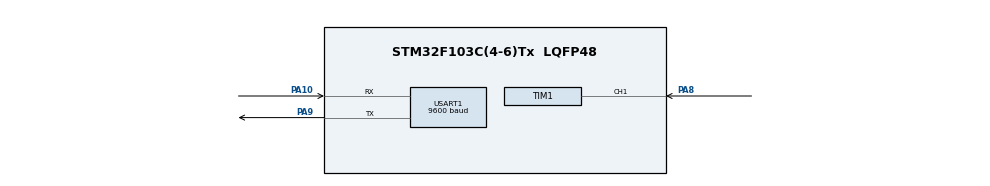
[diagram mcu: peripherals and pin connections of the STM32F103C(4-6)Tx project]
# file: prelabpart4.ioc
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Mcu.Family=STM32F1
Mcu.Name=STM32F103C(4-6)Tx
Mcu.Package=LQFP48
NVIC.PriorityGroup=NVIC_PRIORITYGROUP_4
NVIC.TIM1_BRK_IRQn=true\:0\:0\:false\:false\:true\:true\:true
NVIC.TIM1_CC_IRQn=true\:0\:0\:false\:false\:true\:true\:true
NVIC.TIM1_TRG_COM_IRQn=true\:0\:0\:false\:false\:true\:true\:true
NVIC.TIM1_UP_IRQn=true\:0\:0\:false\:false\:true\:true\:true
NVIC.USART1_IRQn=true\:0\:0\:false\:false\:true\:true\:true
PA10.Mode=Asynchronous
PA10.Signal=USART1_RX
PA8.Signal=S_TIM1_CH1
PA9.Mode=Asynchronous
PA9.Signal=USART1_TX
ProjectManager.HeapSize=0x200
ProjectManager.StackSize=0x400
ProjectManager.TargetToolchain=MDK-ARM V5.32
RCC.APB1Freq_Value=8000000
RCC.APB2Freq_Value=8000000
SH.S_TIM1_CH1.0=TIM1_CH1,Input_Capture1_from_TI1
TIM1.Channel-Input_Capture1_from_TI1=TIM_CHANNEL_1
TIM1.Period=63999
TIM1.Prescaler=124
USART1.BaudRate=9600
USART1.Mode=MODE_TX
USART1.VirtualMode=VM_ASYNC
VP_SYS_VS_ND.Mode=No_Debug
VP_TIM1_VS_ClockSourceINT.Mode=Internal
board=custom

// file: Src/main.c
/* USER CODE BEGIN Header */
/**
  ******************************************************************************
  * @file           : main.c
  * @brief          : Main program body
  ******************************************************************************
  * @attention
  *
  * Copyright (c) 2022 STMicroelectronics.
  * All rights reserved.
  *
  * This software is licensed under terms that can be found in the LICENSE file
  * in the root directory of this software component.
  * If no LICENSE file comes with this software, it is provided AS-IS.
  *
  ******************************************************************************
  */
/* USER CODE END Header */
#include "main.h"

TIM_HandleTypeDef htim1;

UART_HandleTypeDef huart1;

void SystemClock_Config(void);
static void MX_GPIO_Init(void);
static void MX_TIM1_Init(void);
static void MX_USART1_UART_Init(void);

int main(void)
{

  /* MCU Configuration--------------------------------------------------------*/

  /* Reset of all peripherals, Initializes the Flash interface and the Systick. */
  HAL_Init();

  /* Configure the system clock */
  SystemClock_Config();

  /* Initialize all configured peripherals */
  MX_GPIO_Init();
  MX_TIM1_Init();
  MX_USART1_UART_Init();
  /* USER CODE BEGIN 2 */
 HAL_TIM_IC_Start_IT(&htim1, TIM_CHANNEL_1);
  /* USER CODE END 2 */

  /* Infinite loop */
  /* USER CODE BEGIN WHILE */
	char data[256];
	float pscPeriod= (124+1)/(float)8000;
	float calculatedPeriod=0;
	float calculatedFreq;
  while (1)
  {
		calculatedPeriod= (float)periodInARRticks*pscPeriod;
		calculatedFreq= 1.0/calculatedPeriod*1000;
		int len= sprintf(data, "Calculated freq = %d.%02u Hz\r\n",(int) calculatedFreq, (int)((calculatedFreq-(int) calculatedFreq)*100) );
		HAL_UART_Transmit(&huart1, (uint8_t*)data, len+1, HAL_MAX_DELAY);
		periodInARRticks=0;
		HAL_Delay(500);

    /* USER CODE END WHILE */

  }
}

void SystemClock_Config(void)
{
  RCC_OscInitTypeDef RCC_OscInitStruct = {0};
  RCC_ClkInitTypeDef RCC_ClkInitStruct = {0};

  /** Initializes the RCC Oscillators according to the specified parameters
  * in the RCC_OscInitTypeDef structure.
  */
  RCC_OscInitStruct.OscillatorType = RCC_OSCILLATORTYPE_HSI;
  RCC_OscInitStruct.HSIState = RCC_HSI_ON;
  RCC_OscInitStruct.HSICalibrationValue = RCC_HSICALIBRATION_DEFAULT;
  RCC_OscInitStruct.PLL.PLLState = RCC_PLL_NONE;
  if (HAL_RCC_OscConfig(&RCC_OscInitStruct) != HAL_OK)
  {
    Error_Handler();
  }
  /** Initializes the CPU, AHB and APB buses clocks
  */
  RCC_ClkInitStruct.ClockType = RCC_CLOCKTYPE_HCLK|RCC_CLOCKTYPE_SYSCLK
                              |RCC_CLOCKTYPE_PCLK1|RCC_CLOCKTYPE_PCLK2;
  RCC_ClkInitStruct.SYSCLKSource = RCC_SYSCLKSOURCE_HSI;
  RCC_ClkInitStruct.AHBCLKDivider = RCC_SYSCLK_DIV1;
  RCC_ClkInitStruct.APB1CLKDivider = RCC_HCLK_DIV1;
  RCC_ClkInitStruct.APB2CLKDivider = RCC_HCLK_DIV1;

  if (HAL_RCC_ClockConfig(&RCC_ClkInitStruct, FLASH_LATENCY_0) != HAL_OK)
  {
    Error_Handler();
  }
}

static void MX_TIM1_Init(void)
{

  TIM_ClockConfigTypeDef sClockSourceConfig = {0};
  TIM_MasterConfigTypeDef sMasterConfig = {0};
  TIM_IC_InitTypeDef sConfigIC = {0};

  htim1.Instance = TIM1;
  htim1.Init.Prescaler = 124;
  htim1.Init.CounterMode = TIM_COUNTERMODE_UP;
  htim1.Init.Period = 63999;
  htim1.Init.ClockDivision = TIM_CLOCKDIVISION_DIV1;
  htim1.Init.RepetitionCounter = 0;
  htim1.Init.AutoReloadPreload = TIM_AUTORELOAD_PRELOAD_DISABLE;
  if (HAL_TIM_Base_Init(&htim1) != HAL_OK)
  {
    Error_Handler();
  }
  sClockSourceConfig.ClockSource = TIM_CLOCKSOURCE_INTERNAL;
  if (HAL_TIM_ConfigClockSource(&htim1, &sClockSourceConfig) != HAL_OK)
  {
    Error_Handler();
  }
  if (HAL_TIM_IC_Init(&htim1) != HAL_OK)
  {
    Error_Handler();
  }
  sMasterConfig.MasterOutputTrigger = TIM_TRGO_RESET;
  sMasterConfig.MasterSlaveMode = TIM_MASTERSLAVEMODE_DISABLE;
  if (HAL_TIMEx_MasterConfigSynchronization(&htim1, &sMasterConfig) != HAL_OK)
  {
    Error_Handler();
  }
  sConfigIC.ICPolarity = TIM_INPUTCHANNELPOLARITY_RISING;
  sConfigIC.ICSelection = TIM_ICSELECTION_DIRECTTI;
  sConfigIC.ICPrescaler = TIM_ICPSC_DIV1;
  sConfigIC.ICFilter = 0;
  if (HAL_TIM_IC_ConfigChannel(&htim1, &sConfigIC, TIM_CHANNEL_1) != HAL_OK)
  {
    Error_Handler();
  }

}

static void MX_USART1_UART_Init(void)
{

  huart1.Instance = USART1;
  huart1.Init.BaudRate = 9600;
  huart1.Init.WordLength = UART_WORDLENGTH_8B;
  huart1.Init.StopBits = UART_STOPBITS_1;
  huart1.Init.Parity = UART_PARITY_NONE;
  huart1.Init.Mode = UART_MODE_TX;
  huart1.Init.HwFlowCtl = UART_HWCONTROL_NONE;
  huart1.Init.OverSampling = UART_OVERSAMPLING_16;
  if (HAL_UART_Init(&huart1) != HAL_OK)
  {
    Error_Handler();
  }

}

static void MX_GPIO_Init(void)
{

  /* GPIO Ports Clock Enable */
  __HAL_RCC_GPIOA_CLK_ENABLE();

}

void Error_Handler(void)
{
  __disable_irq();
  while (1)
  {
  }
}
